# haltium_application register map
Vendor: Nordic Semiconductor; Series: nRFHaltium; File version: 1
CPU: CM33 r0p4, little endian, MPU, FPU, 3 interrupt priority bits, 480 interrupts
Registers are 32-bit, read-write, reset 0x0 unless marked. A register's access mark holds for its fields unless they carry their own. Offsets are from the block's base; [hi:lo] are bit positions; lines under a group give offsets from that group; {n}, {i} and the like mark numbered series; 'fields as' and 'values as' point back to an identical list.

## MVDMA_NS — MVDMA performs direct-memory-accesses between memories. Data is transferred according to job descriptor lists. Each transfer has corresponding source and sink descriptor lists with matching data amounts. The lists are in memory and they contain data buffer information, address pointers, buffer sizes and data type attributes. MVDMA IP connects to an ARM standard AXI4 bus. 0
Base 0x42003000
Same registers: MVDMA_S 0x52003000
0x00 TASKS_STOP wo — Stop operation.
  [0] TASKS_STOP
    1=Trigger task
0x04 TASKS_RESET wo — Reset operation.
  [0] TASKS_RESET
    1=Trigger task
{0x8+4i} TASKS_START[{i}] (i=0..7) wo — Description collection: Start operation.
  [0] TASKS_START — Start operation.
    1=Trigger task
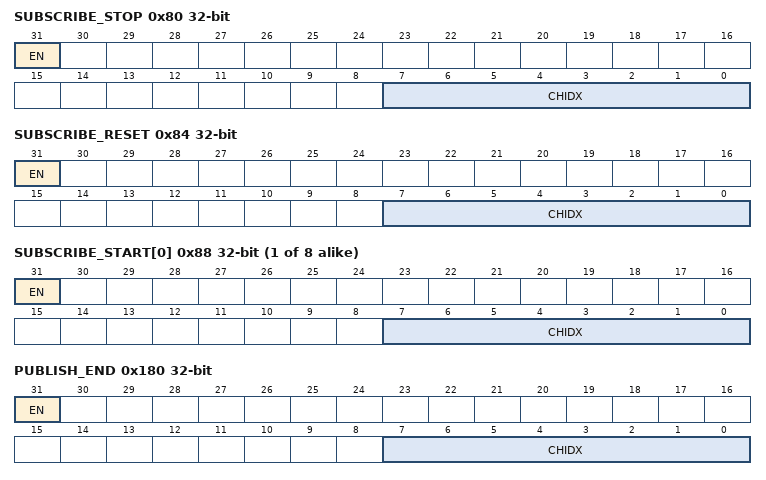
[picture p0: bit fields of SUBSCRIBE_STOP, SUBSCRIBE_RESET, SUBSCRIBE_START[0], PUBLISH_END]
0x80 SUBSCRIBE_STOP — Subscribe configuration for task STOP
  [31] EN
    0=Disabled (Disable subscription); 1=Enabled (Enable subscription)
  [7:0] CHIDX — DPPI channel that task STOP will subscribe to
0x84 SUBSCRIBE_RESET — Subscribe configuration for task RESET
  [31] EN
    values as SUBSCRIBE_STOP.EN
  [7:0] CHIDX — DPPI channel that task RESET will subscribe to
{0x88+4i} SUBSCRIBE_START[{i}] (i=0..7) — Description collection: Subscribe configuration for task START[n]
  [31] EN
    values as SUBSCRIBE_STOP.EN
  [7:0] CHIDX — DPPI channel that task START[n] will subscribe to
0x100 EVENTS_END — Unspecified
  [0] EVENTS_END
    0=NotGenerated (Event not generated); 1=Generated (Event generated)
0x104 EVENTS_STARTED — Unspecified
  [0] EVENTS_STARTED
    values as EVENTS_END.EVENTS_END
0x108 EVENTS_STOPPED — Unspecified
  [0] EVENTS_STOPPED
    values as EVENTS_END.EVENTS_END
0x10C EVENTS_RESET — Unspecified
  [0] EVENTS_RESET
    values as EVENTS_END.EVENTS_END
0x110 EVENTS_SOURCEBUSERROR — Unspecified
  [0] EVENTS_SOURCEBUSERROR
    values as EVENTS_END.EVENTS_END
0x114 EVENTS_SINKBUSERROR — Unspecified
  [0] EVENTS_SINKBUSERROR
    values as EVENTS_END.EVENTS_END
0x180 PUBLISH_END — Publish configuration for event END
  [31] EN
    0=Disabled (Disable publishing); 1=Enabled (Enable publishing)
  [7:0] CHIDX — DPPI channel that event END will publish to
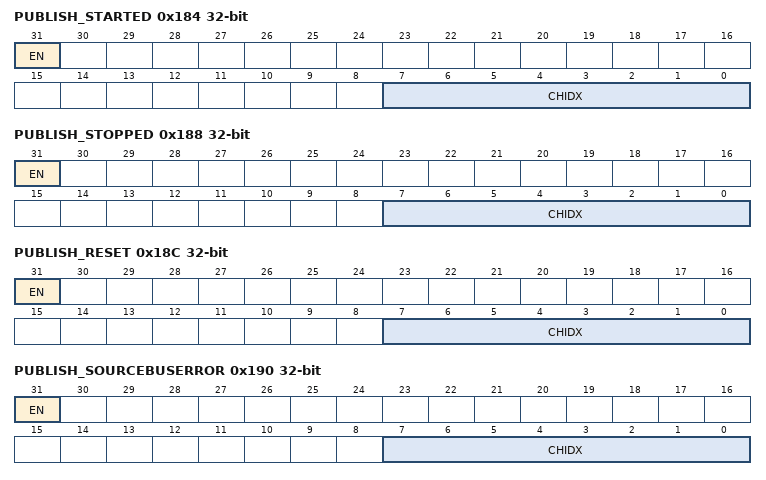
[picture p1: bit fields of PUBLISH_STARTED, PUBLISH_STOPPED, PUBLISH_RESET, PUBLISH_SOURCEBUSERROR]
0x184 PUBLISH_STARTED — Publish configuration for event STARTED
  [31] EN
    values as PUBLISH_END.EN
  [7:0] CHIDX — DPPI channel that event STARTED will publish to
0x188 PUBLISH_STOPPED — Publish configuration for event STOPPED
  [31] EN
    values as PUBLISH_END.EN
  [7:0] CHIDX — DPPI channel that event STOPPED will publish to
0x18C PUBLISH_RESET — Publish configuration for event RESET
  [31] EN
    values as PUBLISH_END.EN
  [7:0] CHIDX — DPPI channel that event RESET will publish to
0x190 PUBLISH_SOURCEBUSERROR — Publish configuration for event SOURCEBUSERROR
  [31] EN
    values as PUBLISH_END.EN
  [7:0] CHIDX — DPPI channel that event SOURCEBUSERROR will publish to
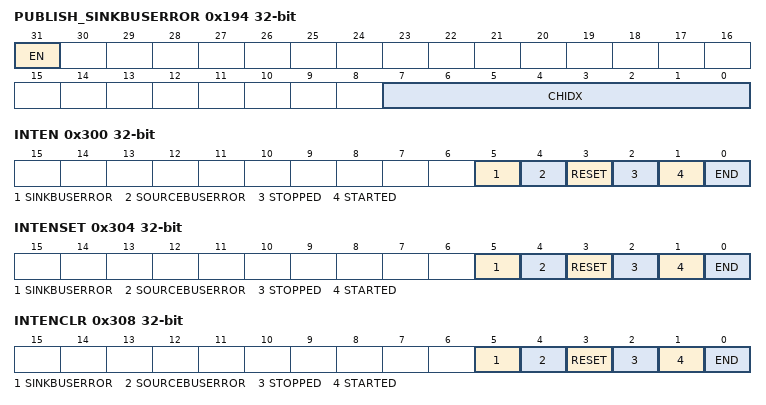
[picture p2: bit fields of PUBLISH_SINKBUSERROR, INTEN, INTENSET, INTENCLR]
0x194 PUBLISH_SINKBUSERROR — Publish configuration for event SINKBUSERROR
  [31] EN
    values as PUBLISH_END.EN
  [7:0] CHIDX — DPPI channel that event SINKBUSERROR will publish to
0x300 INTEN — Enable or disable interrupt
  [all] fields
    0=Disabled; 1=Enabled
  [5] SINKBUSERROR — Enable or disable interrupt for event SINKBUSERROR
  [4] SOURCEBUSERROR — Enable or disable interrupt for event SOURCEBUSERROR
  [3] RESET — Enable or disable interrupt for event RESET
  [2] STOPPED — Enable or disable interrupt for event STOPPED
  [1] STARTED — Enable or disable interrupt for event STARTED
  [0] END — Enable or disable interrupt for event END
0x304 INTENSET — Enable interrupt
  [all] fields
    on read: 0=Disabled (Read: Disabled); 1=Enabled (Read: Enabled) | on write: 1=Set (Enable)
  [5] SINKBUSERROR — Write '1' to enable interrupt for event SINKBUSERROR
  [4] SOURCEBUSERROR — Write '1' to enable interrupt for event SOURCEBUSERROR
  [3] RESET — Write '1' to enable interrupt for event RESET
  [2] STOPPED — Write '1' to enable interrupt for event STOPPED
  [1] STARTED — Write '1' to enable interrupt for event STARTED
  [0] END — Write '1' to enable interrupt for event END
0x308 INTENCLR — Disable interrupt
  [all] fields
    on read: 0=Disabled (Read: Disabled); 1=Enabled (Read: Enabled) | on write: 1=Clear (Disable)
  [5] SINKBUSERROR — Write '1' to disable interrupt for event SINKBUSERROR
  [4] SOURCEBUSERROR — Write '1' to disable interrupt for event SOURCEBUSERROR
  [3] RESET — Write '1' to disable interrupt for event RESET
  [2] STOPPED — Write '1' to disable interrupt for event STOPPED
  [1] STARTED — Write '1' to disable interrupt for event STARTED
  [0] END — Write '1' to disable interrupt for event END
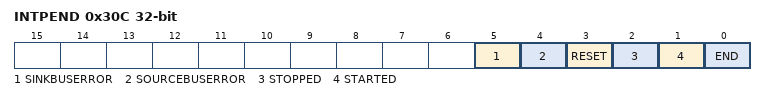
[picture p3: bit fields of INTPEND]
0x30C INTPEND ro — Pending interrupts
  [all] fields
    on read: 0=NotPending (Read: Not pending); 1=Pending (Read: Pending)
  [5] SINKBUSERROR — Read pending status of interrupt for event SINKBUSERROR
  [4] SOURCEBUSERROR — Read pending status of interrupt for event SOURCEBUSERROR
  [3] RESET — Read pending status of interrupt for event RESET
  [2] STOPPED — Read pending status of interrupt for event STOPPED
  [1] STARTED — Read pending status of interrupt for event STARTED
  [0] END — Read pending status of interrupt for event END
0x400 STATUS group — MVDMA status registers.
  0x00 CRCRESULT ro — CRC checksum calculation result
    [31:0] CRC — Result
  0x04 FIFO ro — Status of intermediate fifo: empty, almost full and full information available.
    [1:0] FIFOSTATUS — Result
      0=Empty (No data in intermediate fifo.); 2=AlmostFull (Intermediate is almost full.); 3=Full (Intermediate is full.)
  0x08 ACTIVE ro — Status of DMA transfer.
    [0] ACTIVE — DMA activity
      0=Idle (DMA is in IDLE state.); 1=Active (Data being transferred.)
  0x0C SOURCEBUSERROR ro — Source AXI bus error status.
    [2:0] BUSERROR — AXI bus error type
      0=NoError (There are no errors.); 1=SlaveError (Error generated by AXI slave.); 2=DecodeError (Error generated by interconnect.)
  0x10 SINKBUSERROR ro — Sink AXI bus error status.
    [2:0] BUSERROR — AXI bus error type
      0=NoError (There are no errors.); 1=ReadSlaveError (Read error generated by AXI slave.); 2=ReadDecodeError (Read error generated by interconnect.); 3=WriteSlaveError (Write error generated by AXI slave.); 4=WriteDecodeError (Write error generated by interconnect.)
  0x14 SOURCEADDRESS ro — Latest address being accessed on the Source AXI channel.
    [31:0] ADDRESS — Source address
  0x18 SINKADDRESS ro — Latest address being accessed on the Sink AXI channel.
    [31:0] ADDRESS — Sink address
  0x1C SOURCEJOBCOUNT ro — Number of completed jobs in the current Source descriptor list.
    [31:0] COUNT — Source job count
  0x20 SINKJOBCOUNT ro — Number of completed jobs in the current Sink descriptor list.
    [31:0] COUNT — Sink job count
0x500 ENABLE — Enable the MVDMA peripheral.
  [0] ENABLE — Enable or disable MVDMA
    0=Disabled (Disable MVDMA); 1=Enabled (Enable MVDMA)
0x504 CONFIG group — MVDMA configuration registers.
  0x00 MODE — Mode that defines where the job list pointers are located
    [0] MODE
      0=SingleMode (Descriptor list pointers are in registers, SOURCELISTPTR and SINKLISTPTR.); 1=MultiMode (Descriptor list pointers are in a list in memory and different pointers are chosen with different taskStart tasks.)
  0x04 SOURCELISTPTR — Start address of Source descriptor list or list of descriptor list pointers, depending on MODE.
    [31:0] ADDRESS — Source descriptor list address.
  0x08 SINKLISTPTR — Start address of Sink descriptor list or list of descriptor list pointers, depending on MODE.
    [31:0] ADDRESS — Sink descriptor list address.
